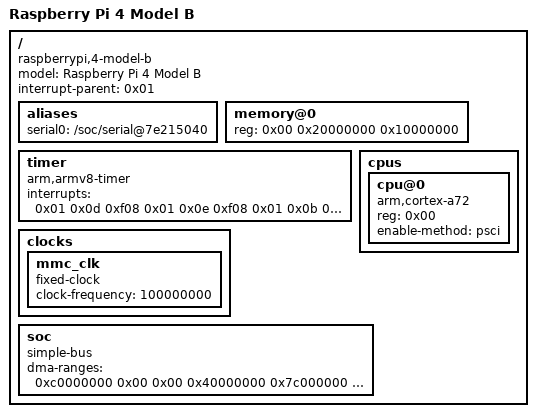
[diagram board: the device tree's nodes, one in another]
/dts-v1/;

/ {
    compatible = "raspberrypi,4-model-b", "brcm,bcm2711";
    model = "Raspberry Pi 4 Model B";
    #address-cells = <0x02>;
    #size-cells = <0x01>;
    interrupt-parent = <0x01>;

    aliases {
        serial0 = "/soc/serial@7e215040";
    };

    memory@0 {
        device_type = "memory";
        reg = <0x00 0x20000000 0x10000000>;
    };

    timer {
        compatible = "arm,armv8-timer";
        interrupts = <0x01 0x0d 0xf08 0x01 0x0e 0xf08 0x01 0x0b 0xf08 0x01 0x0a 0xf08>;
    };

    clocks {
        mmc_clk {
            compatible = "fixed-clock";
            #clock-cells = <0>;
            clock-frequency = <100000000>; /* 100 MHz */
            phandle = <0x40>; /* FIX: Added mandatory missing semicolon */
        };
    };

    cpus {
        #address-cells = <0x01>;
        #size-cells = <0x00>;
        cpu@0 {
            device_type = "cpu";
            compatible = "arm,cortex-a72";
            reg = <0x00>;
            enable-method = "psci";
        };
    };

    soc {
        compatible = "simple-bus";
        #address-cells = <0x01>;
        #size-cells = <0x01>;
        ranges = <0x7e000000 0x00 0xfe000000 0x1800000
                  0x7c000000 0x00 0xfc000000 0x2000000
                  0x40000000 0x00 0xff800000 0x800000>;
        dma-ranges = <0xc0000000 0x00 0x00 0x40000000
                      0x7c000000 0x00 0xfc000000 0x3800000>;
        phandle = <0x63>;
    };
};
